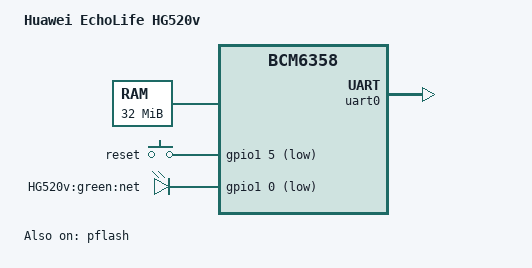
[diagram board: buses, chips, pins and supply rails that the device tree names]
/dts-v1/;

#include "bcm6358.dtsi"

#include <dt-bindings/input/input.h>

/ {
	compatible = "huawei,hg520v", "brcm,bcm6358";
	model = "Huawei EchoLife HG520v";

	memory@0 {
		device_type = "memory";
		reg = <0x00000000 0x02000000>;
	};

	chosen {
		bootargs = "console=ttyS0,115200";
		stdout-path = &uart0;
	};

	gpio-keys-polled {
		compatible = "gpio-keys-polled";
		#address-cells = <1>;
		#size-cells = <0>;
		poll-interval = <20>;
		debounce-interval = <60>;

		reset {
			label = "reset";
			gpios = <&gpio1 5 1>;
			linux,code = <KEY_RESTART>;
		};
	};

	gpio-leds {
		compatible = "gpio-leds";

		inet_green {
			label = "HG520v:green:net";
			gpios = <&gpio1 0 1>;
		};
	};
};

&pflash {
	status = "ok";

	cfe@0 {
		label = "CFE";
		reg = <0x000000 0x010000>;
		read-only;
	};
	linux@10000 {
		label = "linux";
		reg = <0x010000 0x3e0000>;
	};
	nvram@3f0000 {
		label = "nvram";
		reg = <0x3f0000 0x010000>;
	};
};

&uart0 {
	status = "ok";
};
